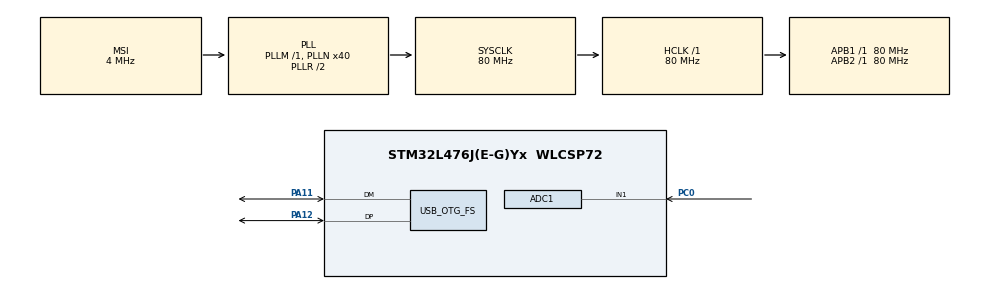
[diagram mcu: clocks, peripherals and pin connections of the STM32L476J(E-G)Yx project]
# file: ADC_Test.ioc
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ADC1.Channel-0\#ChannelRegularConversion=ADC_CHANNEL_1
ADC1.ClockPrescaler=ADC_CLOCK_ASYNC_DIV1
ADC1.ContinuousConvMode=ENABLE
ADC1.DMAContinuousRequests=ENABLE
ADC1.EOCSelection=ADC_EOC_SEQ_CONV
ADC1.NbrOfConversion=1
ADC1.NbrOfConversionFlag=1
ADC1.OffsetNumber-0\#ChannelRegularConversion=ADC_OFFSET_NONE
ADC1.Overrun=ADC_OVR_DATA_PRESERVED
ADC1.OversamplingMode=DISABLE
ADC1.Rank-0\#ChannelRegularConversion=1
ADC1.SamplingTime-0\#ChannelRegularConversion=ADC_SAMPLETIME_2CYCLES_5
ADC1.master=1
Dma.ADC1.0.Direction=DMA_PERIPH_TO_MEMORY
Dma.ADC1.0.Instance=DMA1_Channel1
Dma.ADC1.0.MemDataAlignment=DMA_MDATAALIGN_HALFWORD
Dma.ADC1.0.MemInc=DMA_MINC_ENABLE
Dma.ADC1.0.Mode=DMA_CIRCULAR
Dma.ADC1.0.PeriphDataAlignment=DMA_PDATAALIGN_HALFWORD
Dma.ADC1.0.PeriphInc=DMA_PINC_DISABLE
Dma.ADC1.0.Priority=DMA_PRIORITY_LOW
Dma.Request0=ADC1
Mcu.Family=STM32L4
Mcu.Name=STM32L476J(E-G)Yx
Mcu.Package=WLCSP72
NVIC.DMA1_Channel1_IRQn=true\:0\:0\:false\:false\:true\:false\:true
NVIC.OTG_FS_IRQn=true\:0\:0\:false\:false\:true\:false\:true
NVIC.PriorityGroup=NVIC_PRIORITYGROUP_4
PA11.Mode=Device_Only
PA11.Signal=USB_OTG_FS_DM
PA12.Mode=Device_Only
PA12.Signal=USB_OTG_FS_DP
PC0.Signal=ADCx_IN1
PH0-OSC_IN\ (PH0).Mode=HSE-External-Oscillator
PH0-OSC_IN\ (PH0).Signal=RCC_OSC_IN
PH1-OSC_OUT\ (PH1).Mode=HSE-External-Oscillator
PH1-OSC_OUT\ (PH1).Signal=RCC_OSC_OUT
ProjectManager.HeapSize=0x200
ProjectManager.StackSize=0x400
ProjectManager.TargetToolchain=SW4STM32
RCC.ADCCLockSelection=RCC_ADCCLKSOURCE_SYSCLK
RCC.ADCFreq_Value=80000000
RCC.AHBFreq_Value=80000000
RCC.APB1Freq_Value=80000000
RCC.APB1TimFreq_Value=80000000
RCC.APB2Freq_Value=80000000
RCC.APB2TimFreq_Value=80000000
RCC.CortexFreq_Value=80000000
RCC.HCLKFreq_Value=80000000
RCC.HSE_VALUE=8000000
RCC.HSI_VALUE=16000000
RCC.LSE_VALUE=32768
RCC.MSI_VALUE=4000000
RCC.PLLN=40
RCC.PLLSAI1N=24
RCC.SYSCLKFreq_VALUE=80000000
RCC.SYSCLKSource=RCC_SYSCLKSOURCE_PLLCLK
RCC.USBFreq_Value=48000000
RCC.VCOOutputFreq_Value=160000000
SH.ADCx_IN1.0=ADC1_IN1,IN1-Single-Ended
USB_DEVICE.CLASS_NAME_FS=CDC
USB_DEVICE.VirtualMode=Cdc
USB_DEVICE.VirtualModeFS=Cdc_FS
USB_OTG_FS.VirtualMode=Device_Only
VP_USB_DEVICE_VS_USB_DEVICE_CDC_FS.Mode=CDC_FS
board=custom

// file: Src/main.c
/* USER CODE BEGIN Header */
/**
 ******************************************************************************
 * @file           : main.c
 * @brief          : Main program body
 ******************************************************************************
 * @attention
 *
 * <h2><center>&copy; Copyright (c) 2020 STMicroelectronics.
 * All rights reserved.</center></h2>
 *
 * This software component is licensed by ST under BSD 3-Clause license,
 * the "License"; You may not use this file except in compliance with the
 * License. You may obtain a copy of the License at:
 *                        opensource.org/licenses/BSD-3-Clause
 *
 ******************************************************************************
 */
/* USER CODE END Header */

#include "main.h"
#include "usb_device.h"

ADC_HandleTypeDef hadc1;
DMA_HandleTypeDef hdma_adc1;

void SystemClock_Config(void);
static void MX_GPIO_Init(void);
static void MX_DMA_Init(void);
static void MX_ADC1_Init(void);
/* USER CODE BEGIN PFP */
void Uart_debug_sendstring(char* input);
/* USER CODE END PFP */

/* USER CODE BEGIN 0 */
uint16_t ADC_Get_Value(void) {
	uint16_t val = 0;
	HAL_ADC_Start(&hadc1);
	HAL_ADC_PollForConversion(&hadc1, 100);
	val = HAL_ADC_GetValue(&hadc1);
	HAL_ADC_Stop(&hadc1);
	return val;
}
/* USER CODE END 0 */

int main(void) {

	/* MCU Configuration--------------------------------------------------------*/

	/* Reset of all peripherals, Initializes the Flash interface and the Systick. */
	HAL_Init();

	/* Configure the system clock */
	SystemClock_Config();

	/* Initialize all configured peripherals */
	MX_GPIO_Init();
	MX_DMA_Init();
	MX_ADC1_Init();
	MX_USB_DEVICE_Init();
	/* USER CODE BEGIN 2 */
//	HAL_ADC_Start(&hadc1);
	uint16_t ADCValue = 0;
	char test[80];
	/* USER CODE END 2 */

	/* Infinite loop */
	while (1) {

		/* USER CODE BEGIN 3 */
		ADCValue = ADC_Get_Value();
		sprintf(test, "%d\r\n", ADCValue);
		Uart_debug_sendstring(test);
		HAL_Delay(1);
	}
	/* USER CODE END 3 */
}

void SystemClock_Config(void) {
	RCC_OscInitTypeDef RCC_OscInitStruct = { 0 };
	RCC_ClkInitTypeDef RCC_ClkInitStruct = { 0 };
	RCC_PeriphCLKInitTypeDef PeriphClkInit = { 0 };

	/** Initializes the CPU, AHB and APB busses clocks
	 */
	RCC_OscInitStruct.OscillatorType = RCC_OSCILLATORTYPE_MSI;
	RCC_OscInitStruct.MSIState = RCC_MSI_ON;
	RCC_OscInitStruct.MSICalibrationValue = 0;
	RCC_OscInitStruct.MSIClockRange = RCC_MSIRANGE_6;
	RCC_OscInitStruct.PLL.PLLState = RCC_PLL_ON;
	RCC_OscInitStruct.PLL.PLLSource = RCC_PLLSOURCE_MSI;
	RCC_OscInitStruct.PLL.PLLM = 1;
	RCC_OscInitStruct.PLL.PLLN = 40;
	RCC_OscInitStruct.PLL.PLLP = RCC_PLLP_DIV7;
	RCC_OscInitStruct.PLL.PLLQ = RCC_PLLQ_DIV2;
	RCC_OscInitStruct.PLL.PLLR = RCC_PLLR_DIV2;
	if (HAL_RCC_OscConfig(&RCC_OscInitStruct) != HAL_OK) {
		Error_Handler();
	}
	/** Initializes the CPU, AHB and APB busses clocks
	 */
	RCC_ClkInitStruct.ClockType = RCC_CLOCKTYPE_HCLK | RCC_CLOCKTYPE_SYSCLK
			| RCC_CLOCKTYPE_PCLK1 | RCC_CLOCKTYPE_PCLK2;
	RCC_ClkInitStruct.SYSCLKSource = RCC_SYSCLKSOURCE_PLLCLK;
	RCC_ClkInitStruct.AHBCLKDivider = RCC_SYSCLK_DIV1;
	RCC_ClkInitStruct.APB1CLKDivider = RCC_HCLK_DIV1;
	RCC_ClkInitStruct.APB2CLKDivider = RCC_HCLK_DIV1;

	if (HAL_RCC_ClockConfig(&RCC_ClkInitStruct, FLASH_LATENCY_4) != HAL_OK) {
		Error_Handler();
	}
	PeriphClkInit.PeriphClockSelection = RCC_PERIPHCLK_USB | RCC_PERIPHCLK_ADC;
	PeriphClkInit.AdcClockSelection = RCC_ADCCLKSOURCE_SYSCLK;
	PeriphClkInit.UsbClockSelection = RCC_USBCLKSOURCE_PLLSAI1;
	PeriphClkInit.PLLSAI1.PLLSAI1Source = RCC_PLLSOURCE_MSI;
	PeriphClkInit.PLLSAI1.PLLSAI1M = 1;
	PeriphClkInit.PLLSAI1.PLLSAI1N = 24;
	PeriphClkInit.PLLSAI1.PLLSAI1P = RCC_PLLP_DIV7;
	PeriphClkInit.PLLSAI1.PLLSAI1Q = RCC_PLLQ_DIV2;
	PeriphClkInit.PLLSAI1.PLLSAI1R = RCC_PLLR_DIV2;
	PeriphClkInit.PLLSAI1.PLLSAI1ClockOut = RCC_PLLSAI1_48M2CLK;
	if (HAL_RCCEx_PeriphCLKConfig(&PeriphClkInit) != HAL_OK) {
		Error_Handler();
	}
	/** Configure the main internal regulator output voltage
	 */
	if (HAL_PWREx_ControlVoltageScaling(PWR_REGULATOR_VOLTAGE_SCALE1)
			!= HAL_OK) {
		Error_Handler();
	}
}

static void MX_ADC1_Init(void) {

	ADC_MultiModeTypeDef multimode = { 0 };
	ADC_ChannelConfTypeDef sConfig = { 0 };

	/** Common config
	 */
	hadc1.Instance = ADC1;
	hadc1.Init.ClockPrescaler = ADC_CLOCK_ASYNC_DIV1;
	hadc1.Init.Resolution = ADC_RESOLUTION_12B;
	hadc1.Init.DataAlign = ADC_DATAALIGN_RIGHT;
	hadc1.Init.ScanConvMode = ADC_SCAN_DISABLE;
	hadc1.Init.EOCSelection = ADC_EOC_SEQ_CONV;
	hadc1.Init.LowPowerAutoWait = DISABLE;
	hadc1.Init.ContinuousConvMode = ENABLE;
	hadc1.Init.NbrOfConversion = 1;
	hadc1.Init.DiscontinuousConvMode = DISABLE;
	hadc1.Init.NbrOfDiscConversion = 1;
	hadc1.Init.ExternalTrigConv = ADC_SOFTWARE_START;
	hadc1.Init.ExternalTrigConvEdge = ADC_EXTERNALTRIGCONVEDGE_NONE;
	hadc1.Init.DMAContinuousRequests = ENABLE;
	hadc1.Init.Overrun = ADC_OVR_DATA_PRESERVED;
	hadc1.Init.OversamplingMode = DISABLE;
	if (HAL_ADC_Init(&hadc1) != HAL_OK) {
		Error_Handler();
	}
	/** Configure the ADC multi-mode
	 */
	multimode.Mode = ADC_MODE_INDEPENDENT;
	if (HAL_ADCEx_MultiModeConfigChannel(&hadc1, &multimode) != HAL_OK) {
		Error_Handler();
	}
	/** Configure Regular Channel
	 */
	sConfig.Channel = ADC_CHANNEL_1;
	sConfig.Rank = ADC_REGULAR_RANK_1;
	sConfig.SamplingTime = ADC_SAMPLETIME_2CYCLES_5;
	sConfig.SingleDiff = ADC_SINGLE_ENDED;
	sConfig.OffsetNumber = ADC_OFFSET_NONE;
	sConfig.Offset = 0;
	if (HAL_ADC_ConfigChannel(&hadc1, &sConfig) != HAL_OK) {
		Error_Handler();
	}

}

static void MX_DMA_Init(void) {

	/* DMA controller clock enable */
	__HAL_RCC_DMA1_CLK_ENABLE()
	;

	/* DMA interrupt init */
	/* DMA1_Channel1_IRQn interrupt configuration */
	HAL_NVIC_SetPriority(DMA1_Channel1_IRQn, 0, 0);
	HAL_NVIC_EnableIRQ(DMA1_Channel1_IRQn);

}

static void MX_GPIO_Init(void) {

	/* GPIO Ports Clock Enable */
	__HAL_RCC_GPIOA_CLK_ENABLE()
	;
	__HAL_RCC_GPIOH_CLK_ENABLE()
	;
	__HAL_RCC_GPIOC_CLK_ENABLE()
	;

}

/* USER CODE BEGIN 4 */
void Uart_debug_sendstring(char* input) {
	CDC_Transmit_FS((uint8_t*) input, strlen((char*) input));
}
/* USER CODE END 4 */

void Error_Handler(void) {
}

/************************ (C) COPYRIGHT STMicroelectronics *****END OF FILE****/
